# STM32F100ZET6 register map
File version: 1.0
Registers are 32-bit, access not given, reset 0x0 unless marked. A register's access mark holds for its fields unless they carry their own. Offsets are from the block's base; [hi:lo] are bit positions; {n}, {i} and the like mark numbered series.

## USART2
Base 0x40004400
Same registers: USART3 0x40004800, UART4 0x40004C00, UART5 0x40005000, USART1 0x40013800
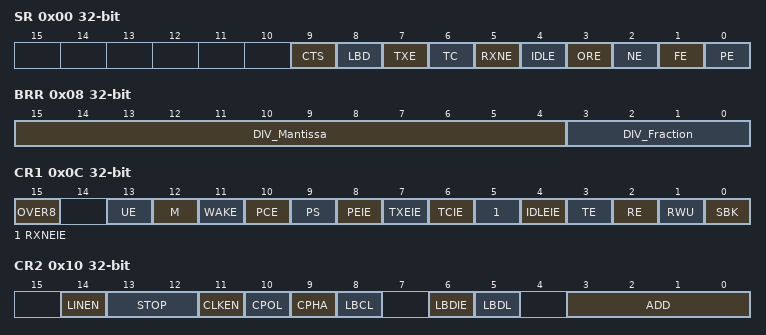
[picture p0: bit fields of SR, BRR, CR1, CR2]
0x00 SR
  [9] CTS, [8] LBD, [7] TXE, [6] TC, [5] RXNE, [4] IDLE, [3] ORE, [2] NE, [1] FE, [0] PE
0x04 DR
  [8:0] DR
0x08 BRR
  [15:4] DIV_Mantissa, [3:0] DIV_Fraction
0x0C CR1
  [15] OVER8, [13] UE, [12] M, [11] WAKE, [10] PCE, [9] PS, [8] PEIE, [7] TXEIE, [6] TCIE, [5] RXNEIE, [4] IDLEIE, [3] TE, [2] RE, [1] RWU, [0] SBK
0x10 CR2
  [14] LINEN, [13:12] STOP, [11] CLKEN, [10] CPOL, [9] CPHA, [8] LBCL, [6] LBDIE, [5] LBDL, [3:0] ADD
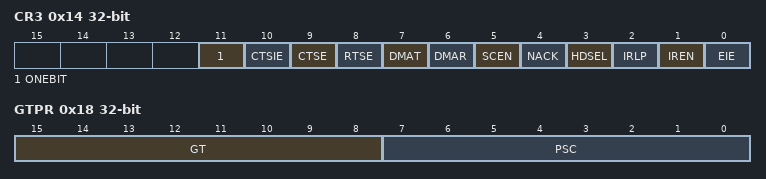
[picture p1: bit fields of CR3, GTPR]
0x14 CR3
  [11] ONEBIT, [10] CTSIE, [9] CTSE, [8] RTSE, [7] DMAT, [6] DMAR, [5] SCEN, [4] NACK, [3] HDSEL, [2] IRLP, [1] IREN, [0] EIE
0x18 GTPR
  [15:8] GT, [7:0] PSC

## I2C1
Base 0x40005400
Same registers: I2C2 0x40005800
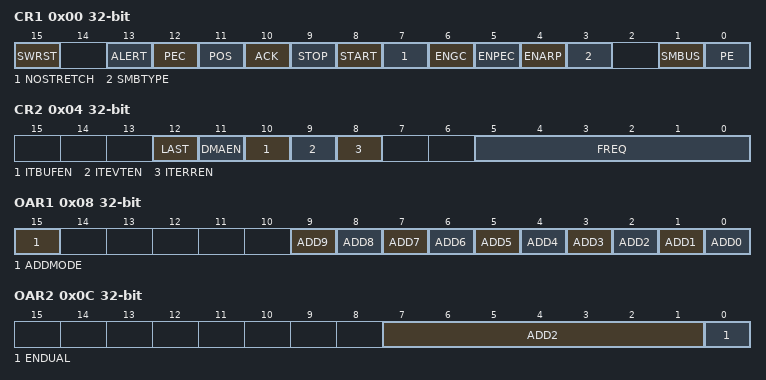
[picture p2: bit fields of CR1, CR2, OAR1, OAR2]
0x00 CR1
  [15] SWRST, [13] ALERT, [12] PEC, [11] POS, [10] ACK, [9] STOP, [8] START, [7] NOSTRETCH, [6] ENGC, [5] ENPEC, [4] ENARP, [3] SMBTYPE, [1] SMBUS, [0] PE
0x04 CR2
  [12] LAST, [11] DMAEN, [10] ITBUFEN, [9] ITEVTEN, [8] ITERREN, [5:0] FREQ
0x08 OAR1
  [15] ADDMODE, [n] ADD{n} (n=0..9)
0x0C OAR2
  [7:1] ADD2, [0] ENDUAL
0x10 DR
  [7:0] DR
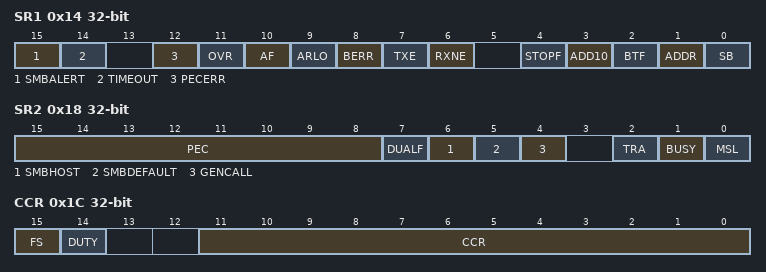
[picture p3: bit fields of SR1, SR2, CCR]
0x14 SR1
  [15] SMBALERT, [14] TIMEOUT, [12] PECERR, [11] OVR, [10] AF, [9] ARLO, [8] BERR, [7] TXE, [6] RXNE, [4] STOPF, [3] ADD10, [2] BTF, [1] ADDR, [0] SB
0x18 SR2
  [15:8] PEC, [7] DUALF, [6] SMBHOST, [5] SMBDEFAULT, [4] GENCALL, [2] TRA, [1] BUSY, [0] MSL
0x1C CCR
  [15] FS, [14] DUTY, [11:0] CCR
0x20 TRISE
  [5:0] TRISE

## BKP
Base 0x40006C00
{0x0+4i} DR{i} (i=1..10)
  [15:0] D
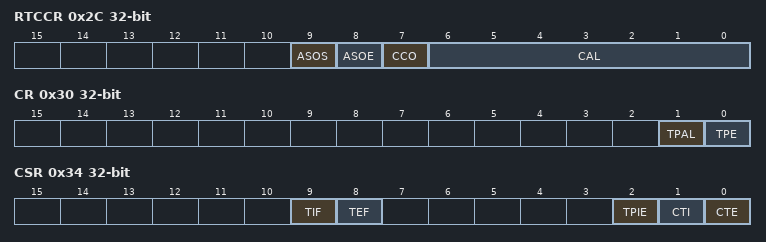
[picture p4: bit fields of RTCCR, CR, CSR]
0x2C RTCCR
  [9] ASOS, [8] ASOE, [7] CCO, [6:0] CAL
0x30 CR
  [1] TPAL, [0] TPE
0x34 CSR
  [9] TIF, [8] TEF, [2] TPIE, [1] CTI, [0] CTE
{0x14+4i} DR{i} (i=11..42)
  [15:0] D

## PWR
Base 0x40007000
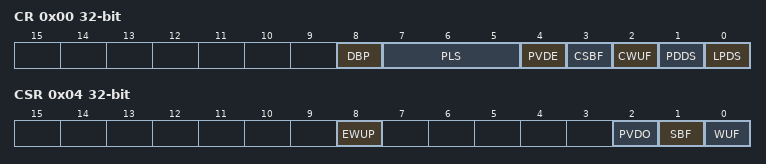
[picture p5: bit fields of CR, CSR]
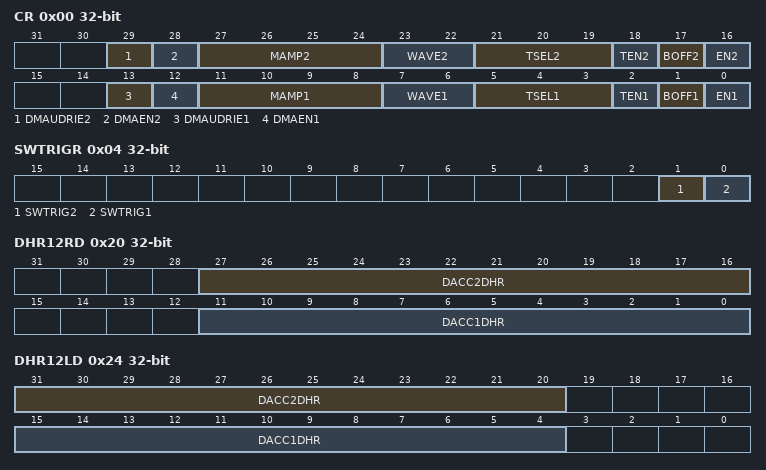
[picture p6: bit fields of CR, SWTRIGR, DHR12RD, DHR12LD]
0x00 CR
  [8] DBP, [7:5] PLS, [4] PVDE, [3] CSBF, [2] CWUF, [1] PDDS, [0] LPDS
0x04 CSR
  [8] EWUP, [2] PVDO, [1] SBF, [0] WUF

## DAC1
Base 0x40007400
0x00 CR
  [29] DMAUDRIE2, [28] DMAEN2, [27:24] MAMP2, [23:22] WAVE2, [21:19] TSEL2, [18] TEN2, [17] BOFF2, [16] EN2, [13] DMAUDRIE1, [12] DMAEN1, [11:8] MAMP1, [7:6] WAVE1, [5:3] TSEL1, [2] TEN1, [1] BOFF1, [0] EN1
0x04 SWTRIGR
  [1] SWTRIG2, [0] SWTRIG1
0x08 DHR12R1
  [11:0] DACC1DHR
0x0C DHR12L1
  [15:4] DACC1DHR
0x10 DHR8R1
  [7:0] DACC1DHR
0x14 DHR12R2
  [11:0] DACC2DHR
0x18 DHR12L2
  [15:4] DACC2DHR
0x1C DHR8R2
  [7:0] DACC2DHR
0x20 DHR12RD
  [27:16] DACC2DHR, [11:0] DACC1DHR
0x24 DHR12LD
  [31:20] DACC2DHR, [15:4] DACC1DHR
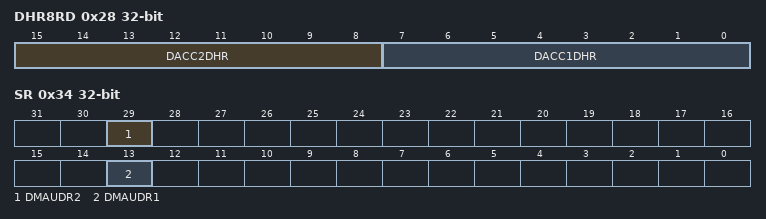
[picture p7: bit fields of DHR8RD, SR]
0x28 DHR8RD
  [15:8] DACC2DHR, [7:0] DACC1DHR
0x2C DOR1
  [11:0] DACC1DOR
0x30 DOR2
  [11:0] DACC2DOR
0x34 SR
  [29] DMAUDR2, [13] DMAUDR1

## CEC
Base 0x40007800
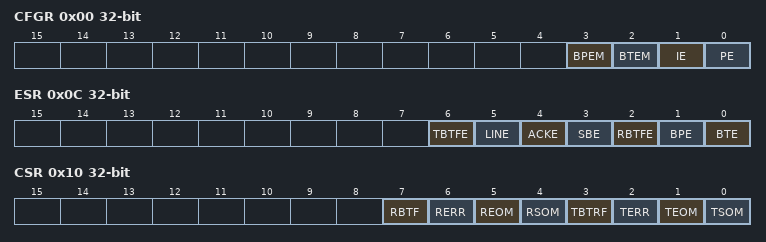
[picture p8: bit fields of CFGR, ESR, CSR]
0x00 CFGR
  [3] BPEM, [2] BTEM, [1] IE, [0] PE
0x04 OAR
  [3:0] OA
0x08 PRES
  [13:0] PRES
0x0C ESR
  [6] TBTFE, [5] LINE, [4] ACKE, [3] SBE, [2] RBTFE, [1] BPE, [0] BTE
0x10 CSR
  [7] RBTF, [6] RERR, [5] REOM, [4] RSOM, [3] TBTRF, [2] TERR, [1] TEOM, [0] TSOM
0x14 TXD
  [7:0] TXD
0x18 RXD
  [7:0] RXD

## AFIO
Base 0x40010000
0x00 EVCR
  [7] EVOE, [6] PORT_PE, [5] PORT_PC, [5:4] PORT_PD, [3] PIN_PX8, [2] PIN_PX4, [2:1] PIN_PX6, [3:0] PIN_PX9
0x04 MAPR
  [26] SWJ_CFG_DISABLE, [25] SWJ_CFG_JTAGDISABLE, [24] SWJ_CFG_NOJNTRST, [16] TIM5CH4_IREMAP, [15] PD01_REMAP, [12] TIM4_REMAP, [11] TIM3_REMAP_PARTIALREMAP, [11:10] TIM3_REMAP_FULLREMAP, [9] TIM2_REMAP_PARTIALREMAP2, [8] TIM2_REMAP_PARTIALREMAP1, [6] TIM1_REMAP_PARTIALREMAP, [4] USART3_REMAP_PARTIALREMAP, [3] USART2_REMAP, [2] USART1_REMAP, [1] I2C1_REMAP, [0] SPI1_REMAP
0x08 EXTICR.0
  [4n+2] EXTI{n}_PE (n=0..3), [4n+2:4n+1] EXTI{n}_PG (n=0..3), [4n+2:4n] EXTI{n}_PF (n=0..3)
0x0C EXTICR.1
  [4n-14] EXTI{n}_PE (n=4..7), [4n-14:4n-15] EXTI{n}_PG (n=4..7), [4n-14:4n-16] EXTI{n}_PF (n=4..7)
0x10 EXTICR.2
  [4n-30] EXTI{n}_PE (n=8..11), [4n-30:4n-31] EXTI{n}_PG (n=8..11), [4n-30:4n-32] EXTI{n}_PF (n=8..11)
0x14 EXTICR.3
  [4n-46] EXTI{n}_PE (n=12..15), [4n-46:4n-47] EXTI{n}_PG (n=12..15), [4n-46:4n-48] EXTI{n}_PF (n=12..15)
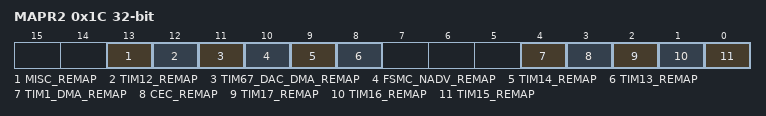
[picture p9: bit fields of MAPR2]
0x1C MAPR2
  [13] MISC_REMAP, [12] TIM12_REMAP, [11] TIM67_DAC_DMA_REMAP, [10] FSMC_NADV_REMAP, [9] TIM14_REMAP, [8] TIM13_REMAP, [4] TIM1_DMA_REMAP, [3] CEC_REMAP, [2] TIM17_REMAP, [1] TIM16_REMAP, [0] TIM15_REMAP
